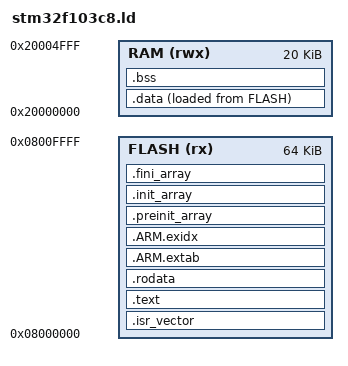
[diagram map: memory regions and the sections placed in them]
/**
 * stm32f103c8.ld — Linker script for STM32F103C8
 *
 * Memory layout (MCP-verified):
 *   Flash: 64KB @ 0x08000000
 *   RAM:   20KB @ 0x20000000
 */

MEMORY
{
    FLASH (rx) : ORIGIN = 0x08000000, LENGTH = 64K
    RAM  (rwx) : ORIGIN = 0x20000000, LENGTH = 20K
}

_estack = ORIGIN(RAM) + LENGTH(RAM);  /* Stack starts at top of RAM */

SECTIONS
{
    /* Vector table and code in flash */
    .isr_vector :
    {
        KEEP(*(.isr_vector))
        . = ALIGN(4);
    } >FLASH

    .text :
    {
        . = ALIGN(4);
        *(.text)
        *(.text*)
        *(.glue_7)
        *(.glue_7t)
        . = ALIGN(4);
    } >FLASH

    /* Read-only data */
    .rodata :
    {
        . = ALIGN(4);
        *(.rodata)
        *(.rodata*)
        . = ALIGN(4);
    } >FLASH

    /* ARM exception unwinding info */
    .ARM.extab :
    {
        *(.ARM.extab*)
    } >FLASH

    .ARM.exidx :
    {
        *(.ARM.exidx*)
    } >FLASH

    /* Pre-initialization array */
    .preinit_array :
    {
        PROVIDE_HIDDEN(__preinit_array_start = .);
        KEEP(*(.preinit_array*))
        PROVIDE_HIDDEN(__preinit_array_end = .);
    } >FLASH

    .init_array :
    {
        PROVIDE_HIDDEN(__init_array_start = .);
        KEEP(*(SORT(.init_array.*)))
        KEEP(*(.init_array*))
        PROVIDE_HIDDEN(__init_array_end = .);
    } >FLASH

    .fini_array :
    {
        PROVIDE_HIDDEN(__fini_array_start = .);
        KEEP(*(SORT(.fini_array.*)))
        KEEP(*(.fini_array*))
        PROVIDE_HIDDEN(__fini_array_end = .);
    } >FLASH

    _sidata = LOADADDR(.data);

    /* Initialized data in flash, copied to RAM at startup */
    .data :
    {
        . = ALIGN(4);
        _sdata = .;
        *(.data)
        *(.data*)
        . = ALIGN(4);
        _edata = .;
    } >RAM AT>FLASH

    /* Uninitialized data (zeroed at startup) */
    .bss :
    {
        . = ALIGN(4);
        _sbss = .;
        *(.bss)
        *(.bss*)
        *(COMMON)
        . = ALIGN(4);
        _ebss = .;
    } >RAM

    /* End of heap marker */
    . = ALIGN(4);
    end = .;
}
